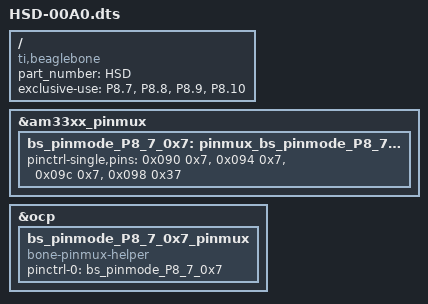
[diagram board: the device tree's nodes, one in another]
/*
 * This is a template-generated file from BoneScript
 */

/dts-v1/;
/plugin/;

/{
    compatible = "ti,beaglebone", "ti,beaglebone-black";
    part_number = "HSD";

    exclusive-use =
        "P8.7",
        "P8.8",
        "P8.9",
        "P8.10";

    fragment@0 {
        target = <&am33xx_pinmux>;
        __overlay__ {
            bs_pinmode_P8_7_0x7: pinmux_bs_pinmode_P8_7_0x7 {
                pinctrl-single,pins = <0x090 0x7>,<0x094 0x7>,<0x09c 0x7>,<0x098 0x37>;
            };
        };
    };

    fragment@1 {
        target = <&ocp>;
        __overlay__ {
            bs_pinmode_P8_7_0x7_pinmux {
                compatible = "bone-pinmux-helper";
                status = "okay";
                pinctrl-names = "default";
                pinctrl-0 = <&bs_pinmode_P8_7_0x7>;
            };
        };
    };
};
